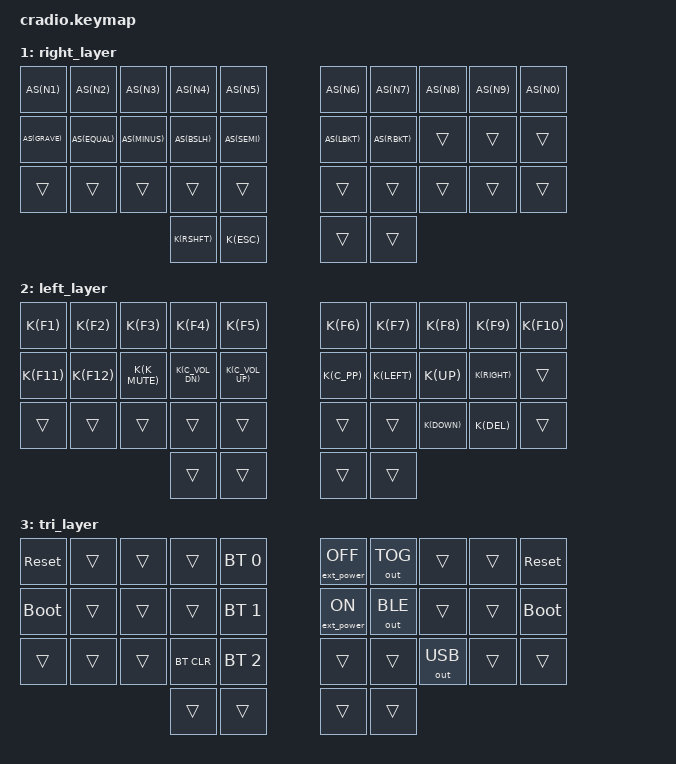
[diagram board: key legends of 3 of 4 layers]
// Copyright (c) 2022 The ZMK Contributors
// SPDX-License-Identifier: MIT

#include <behaviors.dtsi>
#include <dt-bindings/zmk/keys.h>
#include <dt-bindings/zmk/bt.h>
#include <dt-bindings/zmk/outputs.h>
#include <dt-bindings/zmk/ext_power.h>

// ---------- Layer indexes ----------
#define _ALPHA    0   // QWERTY + home‑row mods
#define _NUMSYM   1   // Numbers & symbols
#define _FUNCNAV  2   // Function & navigation
#define _SYSTEM   3   // System controls

// ---------- Keycode shortcuts ----------
#define K(k)      &kp k   // keypress
#define T         &trans  // transparent

// ---------- One-Shot Mods & Layers ----------
//#define OS_SFT    &os_mod LSHIFT     // one-shot Shift
//#define OS_CTL    &os_mod LCTRL      // one-shot Ctrl
//#define OS_NUM    &os_layer _NUMSYM  // one-shot number layer

// ---------- Home-row Mods via single hold-tap ----------
#define HRML(k1,k2,k3,k4) &sht LSHFT k1  &sht LALT k2   &sht LCTRL k3   &sht LGUI k4
#define HRMR(k1,k2,k3,k4) &sht RGUI k1   &sht RCTRL k2  &sht RALT k3    &sht RSHFT k4

// ---------- Layer-Tap Macro ----------
//#define LT(layer, key)    &lt layer key    // layer-tap: hold for layer, tap for key

// ---------- Auto-Shift (hold to send shifted) ----------
#define AS(k)     &autoshift k

/ {
    behaviors {
        ht: hold_tap {
            compatible = "zmk,behavior-hold-tap";
            #binding-cells = <2>;
            flavor = "tap-preferred";
            tapping-term-ms = <220>;
            quick-tap-ms = <150>;
            require-prior-idle-ms = <100>;
            bindings = <&kp>, <&kp>;
        };
	autoshift: auto_shift {
            compatible = "zmk,behavior-auto-shift";
            #binding-cells = <2>;
        };
    };

    // ---------- Combos (chorded shortcuts) ----------
/*    combos {
        compatible = "zmk,combos";
        timeout-ms = <50>;

        jk_esc {
            key-positions = <6 7>;
            binding = <&kp ESC>;
        };
        hj_semi {
            key-positions = <5 6>;
            binding = <&kp SEMI>;
        };
    }; */

    // ---------- Tap-Dance (multi-tap) ----------
    /*tap_dance {
        compatible = "zmk,tap-dance";
        #binding-cells = <2>;

        td_semi_colon {
            bindings = <&kp SEMI &kp COLON>;
        };
    }; */

    // ---------- Conditional tri-layer ----------
    conditional_layers {
        compatible = "zmk,conditional-layers";
        tri_layer {
            if-layers = <_FUNCNAV _NUMSYM>;
            then-layer = <_SYSTEM>;
        };
    };

    keymap {
        compatible = "zmk,keymap";
        alpha_layer {
            bindings = <
        //╭──────────┬──────────┬──────────┬──────────┬──────────╮   ╭──────────┬──────────┬──────────┬──────────┬──────────╮
        //│  Q       │  W       │  E       │  R       │  T       │   │  Y       │  U       │  I       │  O       │  P       │
	     K(Q)      K(W)      K(E)      K(R)      K(T)          K(Y)      K(U)      K(I)      K(O)      K(P)
        //├──────────┼──────────┼──────────┼──────────┼──────────┤   ├──────────┼──────────┼──────────┼──────────┼──────────┤
        //│  A       │  S       │  D       │  F       │  G       │   │  H       │  J       │  K       │  L       │ ' "      │
          HRML(A,       S,         D,         F),        K(G)          K(H)    HRMR(J,      K,         L,         SQT)
        //├──────────┼──────────┼──────────┼──────────┼──────────┤   ├──────────┼──────────┼──────────┼──────────┼──────────┤
        //│  Z       │  X       │  C       │  V       │  B       │   │  N       │  M       │ , <      │ . >      │ / ?      │
             K(Z)      K(X)      K(C)      K(V)      K(B)          K(N)      K(M)     K(COMMA)  K(DOT)    K(FSLH)
        //╰──────────┴──────────┴──────────┼──────────┼──────────┤   ├──────────┼──────────┼──────────┴──────────┴──────────╯
	                //LT(_FUNCNAV, TAB)   K(ENTER)   K(BSPC)   LT(_NUMSYM, SPACE)
                                        &lt 2 TAB  &kp ENTER   &kp BSPC  &lt 1 SPACE
        //                                 ╰──────────┴──────────╯   ╰──────────┴──────────╯
            >;
        };

        right_layer {
            bindings = <
        //╭──────────┬──────────┬──────────┬──────────┬──────────╮   ╭──────────┬──────────┬──────────┬──────────┬──────────╮
        //│ 1        │ 2        │ 3        │ 4        │ 5        │   │ 6        │ 7        │ 8        │ 9        │  0       │
	    AS(N1)    AS(N2)    AS(N3)    AS(N4)    AS(N5)        AS(N6)    AS(N7)    AS(N8)    AS(N9)     AS(N0)
        //├──────────┼──────────┼──────────┼──────────┼──────────┤   ├──────────┼──────────┼──────────┼──────────┼──────────┤
        //│ ` ~      │ = +      │ - _     │  \ |      │  ; :     │   │ [ {      │ ] }      │          │          │          │
            AS(GRAVE) AS(EQUAL) AS(MINUS) AS(BSLH)   AS(SEMI)     AS(LBKT)  AS(RBKT)     T        T         T
        //├──────────┼──────────┼──────────┼──────────┼──────────┤   ├──────────┼──────────┼──────────┼──────────┼──────────┤
        //│          │          │          │          │          │   │          │          │          │          │          │
                T        T         T         T         T             T         T         T         T        T
        //╰──────────┴──────────┴──────────┼──────────┼──────────┤   ├──────────┼──────────┼──────────┴──────────┴──────────╯
                			     K(RSHFT)    K(ESC)         T         T
        //                                 ╰──────────┴──────────╯   ╰──────────┴──────────╯
            >;
        };

        left_layer {
            bindings = <
        //╭──────────┬──────────┬──────────┬──────────┬──────────╮   ╭──────────┬──────────┬──────────┬──────────┬──────────╮
        //│  F1      │  F2      │  F3      │  F4      │ F5       │   │  F6      │  F7      │  F8      │  F9      │  F10     │
	     K(F1)      K(F2)      K(F3)      K(F4)     K(F5)           K(F6)      K(F7)      K(F8)      K(F9)      K(F10)
        //├──────────┼──────────┼──────────┼──────────┼──────────┤   ├──────────┼──────────┼──────────┼──────────┼──────────┤
        //│  F11     │  F12     │  Mute    │  VOL DN  │ VOL UP   │   │          │  LEFT    │  UP      │ RIGHT    │          │
             K(F11)     K(F12)     K(K_MUTE) K(C_VOL_DN) K(C_VOL_UP)     K(C_PP)   K(LEFT)    K(UP)     K(RIGHT)      T 
        //├──────────┼──────────┼──────────┼──────────┼──────────┤   ├──────────┼──────────┼──────────┼──────────┼──────────┤
        //│          │          │          │          │          │   │          │          │ DOWN     │   DEL    │          │
                T         T          T          T          T              T          T       K(DOWN),     K(DEL),     T
        //╰──────────┴──────────┴──────────┼──────────┼──────────┤   ├──────────┼──────────┼──────────┴──────────┴──────────╯
                				T,         T,             T,         T
        //                                 ╰──────────┴──────────╯   ╰──────────┴──────────╯
            >;
        };

        tri_layer {
            bindings = <
        //╭──────────┬──────────┬──────────┬──────────┬──────────╮   ╭──────────┬──────────┬──────────┬──────────┬──────────╮
        //│ RESET    │          │          │          │PROFILE 0 │   │ EP OFF   │          │          │          │  RESET   │
	    &sys_reset,   T,         T,        T,      &bt BT_SEL 0,   &ext_power EP_OFF, &out OUT_TOG, T,   T,   &sys_reset,
        //├──────────┼──────────┼──────────┼──────────┼──────────┤   ├──────────┼──────────┼──────────┼──────────┼──────────┤
        //│BOOTLOADER│          │          │          │PROFILE 1 │   │ EP ON    │          │          │          │BOOTLOADER│
           &bootloader,   T,         T,         T,    &bt BT_SEL 1,    &ext_power EP_ON,  &out OUT_BLE, T,   T,   &bootloader,
        //├──────────┼──────────┼──────────┼──────────┼──────────┤   ├──────────┼──────────┼──────────┼──────────┼──────────┤
        //│          │          │          │ CLEAR BT │PROFILE 2 │   │          │          │          │          │          │
               T,          T,        T,    &bt BT_CLR, &bt BT_SEL 2,      T,          T,  &out OUT_USB,     T,        T,
        //╰──────────┴──────────┴──────────┼──────────┼──────────┤   ├──────────┼──────────┼──────────┴──────────┴──────────╯
                				 T,         T,             T,        T
        //                                 ╰──────────┴──────────╯   ╰──────────┴──────────╯
            >;
        };
    };
};

